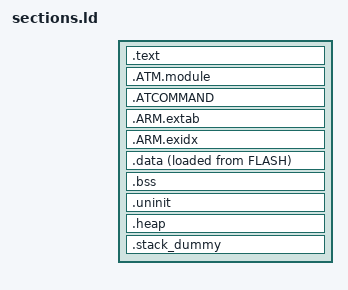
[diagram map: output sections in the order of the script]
/*
 *-----------------------------------------------------------------------------
 * The confidential and proprietary information contained in this file may
 * only be used by a person authorised under and to the extent permitted
 * by a subsisting licensing agreement from ARM Limited.
 *
 *            (C) COPYRIGHT 2010-2013 ARM Limited.
 *                ALL RIGHTS RESERVED
 *
 * This entire notice must be reproduced on all copies of this file
 * and copies of this file may only be made by a person if such person is
 * permitted to do so under the terms of a subsisting license agreement
 * from ARM Limited.
 *
 *      SVN Information
 *
 *      Checked In          : $Date: $
 *
 *      Revision            : $Revision: $
 *
 *      Release Information : Cortex-M System Design Kit-r1p0-00rel0
 *-----------------------------------------------------------------------------
 */
/* Linker script to place sections and symbol values. Should be used together
 * with other linker script that defines memory regions FLASH and RAM.
 * It references following symbols, which must be defined in code:
 *   Reset_Handler : Entry of reset handler
 *
 * It defines following symbols, which code can use without definition:
 *   __exidx_start
 *   __exidx_end
 *   __etext
 *   __data_start__
 *   __preinit_array_start
 *   __preinit_array_end
 *   __init_array_start
 *   __init_array_end
 *   __fini_array_start
 *   __fini_array_end
 *   __data_end__
 *   __bss_start__
 *   __bss_end__
 *   __end__
 *   end
 *   __HeapLimit
 *   __StackLimit
 *   __StackTop
 *   __stack
 */
ENTRY(Reset_Handler)

SECTIONS
{
    .text :
    {
        KEEP(*(.isr_vector))
        *(.text*)
        KEEP(*(.KEEP.text*))

        KEEP(*(.init))
        KEEP(*(.fini))

        /* .ctors */
        *crtbegin.o(.ctors)
        *crtbegin?.o(.ctors)
        *(EXCLUDE_FILE(*crtend?.o *crtend.o) .ctors)
        *(SORT(.ctors.*))
        *(.ctors)

        /* .dtors */
         *crtbegin.o(.dtors)
         *crtbegin?.o(.dtors)
         *(EXCLUDE_FILE(*crtend?.o *crtend.o) .dtors)
         *(SORT(.dtors.*))
         *(.dtors)

        *(SORT_BY_ALIGNMENT(.rodata*))

        KEEP(*(.eh_frame*))
    } > FLASH

    . = ALIGN(4);
    __atm_module_start = .;
    .ATM.module :
    {
        KEEP(*(SORT(.atm_module.*)))
    } > FLASH
    __atm_module_end = .;

        . = ALIGN(4);
        __at_cmd_start = .;
        .ATCOMMAND :
        {
                KEEP(*(SORT(.at_cmd.*)))
        } > FLASH
        __at_cmd_end = .;

    .ARM.extab :
    {
        *(.ARM.extab* .gnu.linkonce.armextab.*)
    } > FLASH

    __exidx_start = .;
    .ARM.exidx :
    {
        *(.ARM.exidx* .gnu.linkonce.armexidx.*)
    } > FLASH
    __exidx_end = .;

    .data :
    {
        __etext = LOADADDR(.data);
        __data_start__ = .;
        *(vtable)
        *(SORT_BY_ALIGNMENT(.data*))

        . = ALIGN(4);
        /* preinit data */
        PROVIDE_HIDDEN (__preinit_array_start = .);
        KEEP(*(.preinit_array))
        PROVIDE_HIDDEN (__preinit_array_end = .);

        . = ALIGN(4);
        /* init data */
        PROVIDE_HIDDEN (__init_array_start = .);
        KEEP(*(SORT(.init_array.*)))
        KEEP(*(.init_array))
        PROVIDE_HIDDEN (__init_array_end = .);


        . = ALIGN(4);
        /* finit data */
        PROVIDE_HIDDEN (__fini_array_start = .);
        KEEP(*(SORT(.fini_array.*)))
        KEEP(*(.fini_array))
        PROVIDE_HIDDEN (__fini_array_end = .);

        KEEP(*(.jcr*))
        . = ALIGN(4);
        /* All data end */
        __data_end__ = .;

    } >RAM AT>FLASH

    .bss :
    {
        . = ALIGN(4);
        __bss_start__ = .;
        *(SORT_BY_ALIGNMENT(.bss*))
        *(COMMON)
        . = ALIGN(4);
        __bss_end__ = .;
    } > RAM

    .uninit (NOLOAD) :
    {
        . = ALIGN(4);
        *(SORT_BY_ALIGNMENT(.uninit*))
        . = ALIGN(4);
    } > RAM

    .heap (COPY):
    {
        __end__ = .;
        end = __end__;
        *(.heap*)
        __HeapLimit = .;
    } > RAM

    /* .stack_dummy section doesn't contains any symbols. It is only
     * used for linker to calculate size of stack sections, and assign
     * values to stack symbols later */
    .stack_dummy (COPY):
    {
        *(.stack*)
    } > RAM

    /* Set stack top to end of RAM, and stack limit move down by
     * size of stack_dummy section */
    __StackTop = ORIGIN(RAM) + LENGTH(RAM);
    __StackLimit = __StackTop - SIZEOF(.stack_dummy);
    PROVIDE(__stack = __StackTop);

    /* Check if data + heap + stack exceeds RAM limit */
    ASSERT(__StackLimit >= __HeapLimit, "region RAM overflowed with stack")
}
